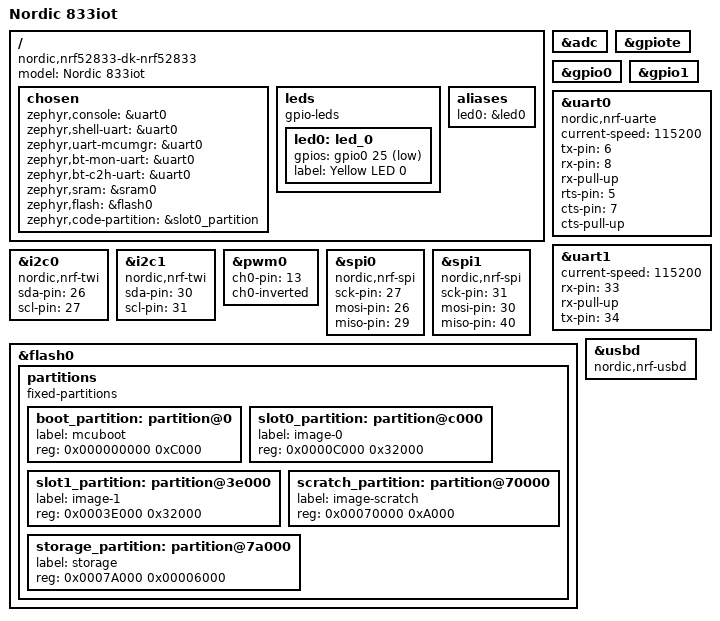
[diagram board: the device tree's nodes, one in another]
/*
 * copied from "Nordic nRF52833 DK NRF52833"
 *
 * SPDX-License-Identifier: Apache-2.0
 */

/dts-v1/;
#include <nordic/nrf52833_qiaa.dtsi>

/ {
	model = "Nordic 833iot";
	compatible = "nordic,nrf52833-dk-nrf52833";

	chosen {
		zephyr,console = &uart0;
		zephyr,shell-uart = &uart0;
		zephyr,uart-mcumgr = &uart0;
		zephyr,bt-mon-uart = &uart0;
		zephyr,bt-c2h-uart = &uart0;
		zephyr,sram = &sram0;
		zephyr,flash = &flash0;
		zephyr,code-partition = &slot0_partition;
	};

	leds {
		compatible = "gpio-leds";
		led0: led_0 {
			gpios = <&gpio0 25 GPIO_ACTIVE_LOW>;
			label = "Yellow LED 0";
		};
	};

	/* These aliases are provided for compatibility with samples */
	aliases {
		led0 = &led0;
	};
};

&adc {
	status = "okay";
};

&gpiote {
	status = "okay";
};

&gpio0 {
	status = "okay";
};

&gpio1 {
	status = "okay";
};

&uart0 {
	compatible = "nordic,nrf-uarte";
	status = "okay";
	current-speed = <115200>;
	tx-pin = <6>;
	rx-pin = <8>;
	rx-pull-up;
	rts-pin = <5>;
	cts-pin = <7>;
	cts-pull-up;
};

&uart1 {
	status = "okay";
	current-speed = <115200>;
	rx-pin = <33>;
	rx-pull-up;
	tx-pin = <34>;
};

&i2c0 {
	compatible = "nordic,nrf-twi";
	status = "okay";
	sda-pin = <26>;
	scl-pin = <27>;
};

&i2c1 {
	compatible = "nordic,nrf-twi";
	/* Cannot be used together with spi1. */
	/* status = "okay"; */
	sda-pin = <30>;
	scl-pin = <31>;
};

&pwm0 {
	status = "okay";
	ch0-pin = <13>;
	ch0-inverted;
};

&spi0 {
	compatible = "nordic,nrf-spi";
	/* Cannot be used together with i2c0. */
	/* status = "okay"; */
	sck-pin = <27>;
	mosi-pin = <26>;
	miso-pin = <29>;
};

&spi1 {
	compatible = "nordic,nrf-spi";
	status = "okay";
	sck-pin = <31>;
	mosi-pin = <30>;
	miso-pin = <40>;
};

&flash0 {

	partitions {
		compatible = "fixed-partitions";
		#address-cells = <1>;
		#size-cells = <1>;

		boot_partition: partition@0 {
			label = "mcuboot";
			reg = <0x000000000 0xC000>;
		};
		slot0_partition: partition@c000 {
			label = "image-0";
			reg = <0x0000C000 0x32000>;
		};
		slot1_partition: partition@3e000 {
			label = "image-1";
			reg = <0x0003E000 0x32000>;
		};
		scratch_partition: partition@70000 {
			label = "image-scratch";
			reg = <0x00070000 0xA000>;
		};
		storage_partition: partition@7a000 {
			label = "storage";
			reg = <0x0007A000 0x00006000>;
		};
	};
};

zephyr_udc0: &usbd {
	compatible = "nordic,nrf-usbd";
	status = "okay";
};
